# STM32WL3R register map
File version: 0.3
CPU: CM0+ r0p0, little endian, MPU, no FPU, 4 interrupt priority bits
Registers are 32-bit, read-write, reset 0x0 unless marked. A register's access mark holds for its fields unless they carry their own. Offsets are from the block's base; [hi:lo] are bit positions.

## STATIC — STATIC_REG_BLOCK address block description
Base 0x49000400
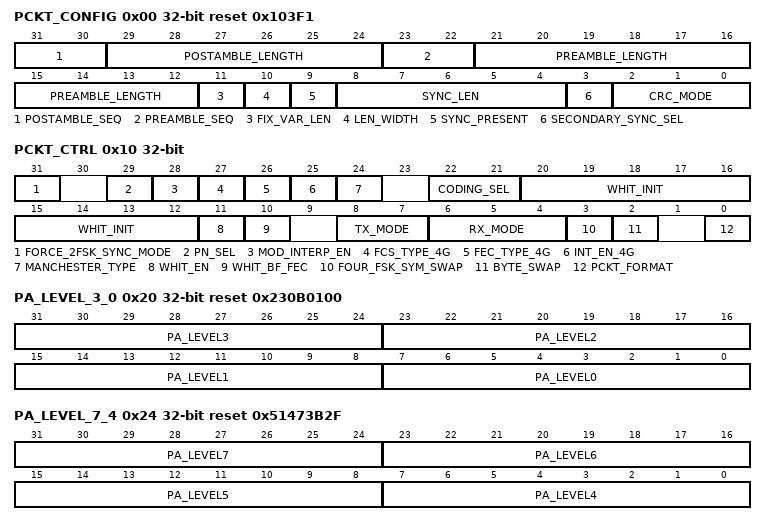
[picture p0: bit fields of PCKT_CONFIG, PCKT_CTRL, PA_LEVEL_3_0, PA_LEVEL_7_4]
0x00 PCKT_CONFIG reset 0x103F1
  [31:30] POSTAMBLE_SEQ — Packet postamble control: postamble bit sequence selection
  [29:24] POSTAMBLE_LENGTH — Length of the POSTAMBLE in pair of bits (0 to 126 bits)
  [23:22] PREAMBLE_SEQ — Select the PREAMBLE pattern to be applied
  [21:12] PREAMBLE_LENGTH — Length of the PREAMBLE in pairs of bits (0 to 2046 bits)
  [11] FIX_VAR_LEN — Select the length mode
  [10] LEN_WIDTH — Indicates if the LENGTH field is defined on 1 byte or 2 bytes
  [9] SYNC_PRESENT — Indicate if a SYNC word is present on the frame or not (null length):
  [8:4] SYNC_LEN — Length of the SYNC (and secondary) SYNC word in 1-bit granularity
  [3] SECONDARY_SYNC_SEL — In TX mode this bit selects which synchro word is sent on the frame between SYNC and SEC_SYNC
  [2:0] CRC_MODE — CRC type (0, 8, 16, 16 802.15.4 compatible, 24, 32 bits)
0x04 SYNC reset 0x23232323
  [31:0] SYNC — Synchro word.
0x08 SEC_SYNC
  [31:0] SEC_SYNC — Secondary Synchro word.
0x0C CRC_INIT
  [31:0] CRC_INIT_VAL — CRC intialization value
0x10 PCKT_CTRL
  [31] FORCE_2FSK_SYNC_MODE — Force SYNC word to be formatted as a 2-(G)FSK bit steam instead of 4-9G
  [29] PN_SEL — Select the Pseudo Random Binary Sequence (PRBS) polynomial when the device is transmitting in PN mode (TX_MODE = b11)
    0=PRBS9 ( x^9 + x^5 +1) (default); 1=PRBS15 ( x^15+ x^14 + 1)
  [28] MOD_INTERP_EN — Enable frequency interpolator (for 2-GFSK and 4-GFSK)
  [27] FCS_TYPE_4G — FCS type value in header field for 802.15.4g
  [26] FEC_TYPE_4G — FEC type for 802.15.4g
  [25] INT_EN_4G — This field is used as Interleaving enable for 802.15.4g.
  [24] MANCHESTER_TYPE — Change the Manchester encoding polarity:
  [22:21] CODING_SEL — Coding / decoding selection:
  [20:12] WHIT_INIT — Whitening initialization value
  [11] WHIT_EN — Whitening enable
  [10] WHIT_BF_FEC — Whitening before FEC feature:
  [8:7] TX_MODE
  [6:4] RX_MODE
  [3] FOUR_FSK_SYM_SWAP — Invert bit to symbol mapping for 4(G)FSK
  [2] BYTE_SWAP — Invert MSB-LSB transmission order (bitendianess)
  [0] PCKT_FORMAT — Packet format
0x14 DATABUFFER0_PTR
  [31:2] DATABUFFER0_PTR — Start address to be used by the Data Buffer0
0x18 DATABUFFER1_PTR
  [31:2] DATABUFFER1_PTR — Start address to be used by the Data Buffer1
0x1C DATABUFFER_SIZE
  [15:0] DATABUFFER_SIZE — Size of the Data Buffers (Data Buffer0 and Data Buffer1) expressed in byte unit.
0x20 PA_LEVEL_3_0 reset 0x230B0100
  [31:24] PA_LEVEL3 — Output power level for fourth step (Max - 23 dB)
  [23:16] PA_LEVEL2 — Output power level for third step (Max - 35 dB)
  [15:8] PA_LEVEL1 — Output power level for second step (Max - 40 dB)
  [7:0] PA_LEVEL0 — Output power level for first step (no output power)
0x24 PA_LEVEL_7_4 reset 0x51473B2F
  [31:24] PA_LEVEL7 — Output power level for eigthth step (Max up to 16 or 20dBm depending on the BOM)
  [23:16] PA_LEVEL6 — Output power level for seventh step (default is Max - 5 dB)
  [15:8] PA_LEVEL5 — Output power level for sixth step (default Max - 11 dB)
  [7:0] PA_LEVEL4 — Output power level for fifth step ((Max - 17 dB)
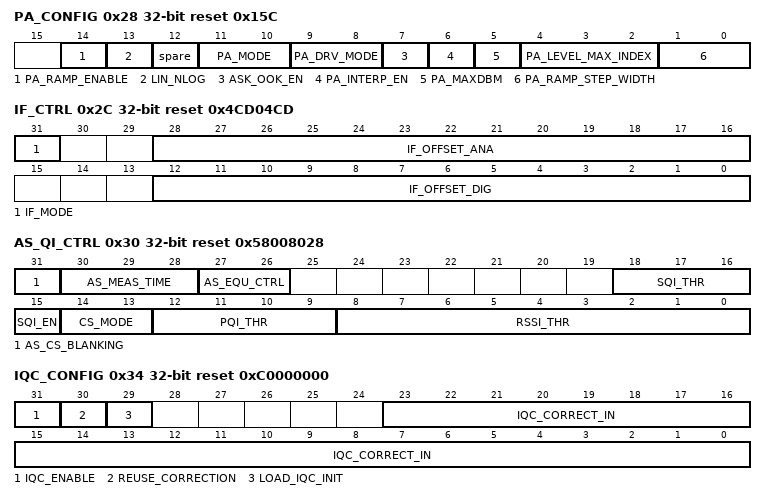
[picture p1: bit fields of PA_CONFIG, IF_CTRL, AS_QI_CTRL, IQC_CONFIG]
0x28 PA_CONFIG reset 0x15C
  [14] PA_RAMP_ENABLE — Enable the power ramping when Static PA_CONFIG.PA_MODE[1:0] = 00
  [13] LIN_NLOG — When 0, enable the linear-to- log conversion of the PA code output from Safe-ASK calibrator
  [12] spare — spare bit
  [11:10] PA_MODE — Configure the Power Amplifier (PA) mode:
  [9:8] PA_DRV_MODE — Request to use the high power PA output (to reach the +20dBm target)
  [7] ASK_OOK_EN — Enable the generation of the internal signal TXDATA which is the input of the FIR (8 taps), enabled by same bit (otherwise FIR is excluded, output fixed at level '1').
  [6] PA_INTERP_EN — Enable power level interpolator.
  [5] PA_MAXDBM — Configure the Power Amplifier (PA) ouput power:
  [4:2] PA_LEVEL_MAX_INDEX — Final level for power ramping
  [1:0] PA_RAMP_STEP_WIDTH — Step width (unit: 1/8 of bit period).
0x2C IF_CTRL reset 0x4CD04CD
  [31] IF_MODE — Select the cutoff frequency of the AAF information for the analog RFSUBG IP):
  [28:16] IF_OFFSET_ANA — Intermediate frequency setting for the synthesizer configuration (default: 300 kHz)
  [12:0] IF_OFFSET_DIG — Intermediate frequency setting for the digital shift-to-baseband circuits (default: 300 kHz)
0x30 AS_QI_CTRL reset 0x58008028
  [31] AS_CS_BLANKING — Blank received data if signal is below the CS threshold
  [30:28] AS_MEAS_TIME — Antenna switching measurement time
  [27:26] AS_EQU_CTRL — ISI cancellation equalizer:
  [18:16] SQI_THR — SQI threshold defining the precision requested to detect the SYNC word.
  [15] SQI_EN — SQI enable:
  [14:13] CS_MODE — Carrier Sense mode selection:
  [12:9] PQI_THR — PQI threshold (if 0 then PQI is disabled).
  [8:0] RSSI_THR — Signal detect threshold in 1 dB resolution.
0x34 IQC_CONFIG reset 0xC0000000
  [31] IQC_ENABLE — Enable IQC
  [30] REUSE_CORRECTION — Reuse last correction value
  [29] LOAD_IQC_INIT wo — Action bit to load the IQC_CORRECT_IN[23:0] bit field in the recirculation register when this bit is written to 1.
  [23:0] IQC_CORRECT_IN — Correction value Input for the IQ compensation engine (to be used as starting point or when the engine is disabled).
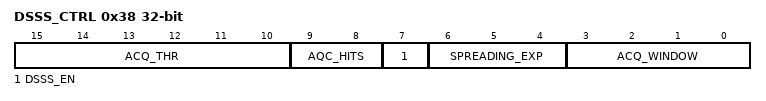
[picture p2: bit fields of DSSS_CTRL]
0x38 DSSS_CTRL
  [15:10] ACQ_THR — DSSS acquisition threshold
  [9:8] AQC_HITS — DSSS acquisition hits
  [7] DSSS_EN — DSSS mode enable
  [6:4] SPREADING_EXP — DSSS spreading exponent
  [3:0] ACQ_WINDOW — DSSS Acquisition window
